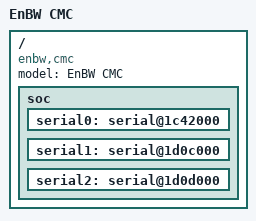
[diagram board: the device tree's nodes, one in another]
// SPDX-License-Identifier: GPL-2.0-or-later
/*
 * Device Tree for AM1808 EnBW CMC board
 *
 * Copyright 2012 DENX Software Engineering GmbH
 * Heiko Schocher <hs@denx.de>
 */
/dts-v1/;
#include "da850.dtsi"

/ {
	compatible = "enbw,cmc", "ti,da850";
	model = "EnBW CMC";

	soc {
		serial0: serial@1c42000 {
			status = "okay";
		};
		serial1: serial@1d0c000 {
			status = "okay";
		};
		serial2: serial@1d0d000 {
			status = "okay";
		};
	};
};
